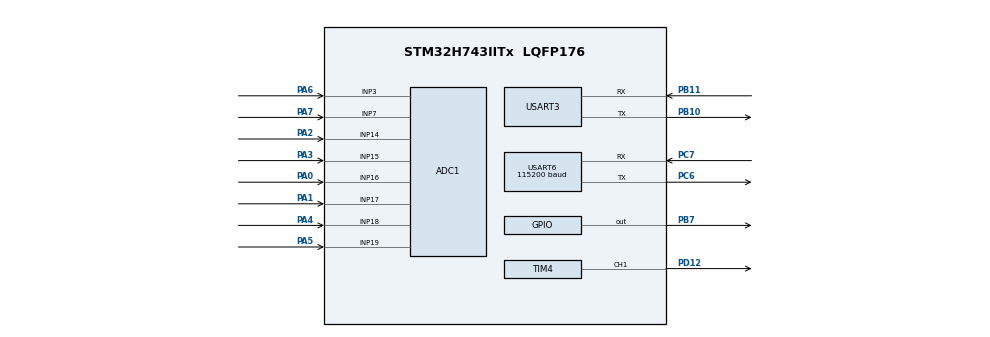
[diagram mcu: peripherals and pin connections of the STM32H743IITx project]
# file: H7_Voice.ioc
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ADC1.Channel-0\#ChannelRegularConversion=ADC_CHANNEL_16
ADC1.Channel-1\#ChannelRegularConversion=ADC_CHANNEL_17
ADC1.Channel-2\#ChannelRegularConversion=ADC_CHANNEL_14
ADC1.Channel-3\#ChannelRegularConversion=ADC_CHANNEL_15
ADC1.Channel-4\#ChannelRegularConversion=ADC_CHANNEL_18
ADC1.Channel-5\#ChannelRegularConversion=ADC_CHANNEL_19
ADC1.Channel-6\#ChannelRegularConversion=ADC_CHANNEL_3
ADC1.Channel-7\#ChannelRegularConversion=ADC_CHANNEL_7
ADC1.ContinuousConvMode=ENABLE
ADC1.ConversionDataManagement=ADC_CONVERSIONDATA_DMA_CIRCULAR
ADC1.NbrOfConversion=8
ADC1.NbrOfConversionFlag=1
ADC1.OffsetNumber-0\#ChannelRegularConversion=ADC_OFFSET_NONE
ADC1.OffsetNumber-1\#ChannelRegularConversion=ADC_OFFSET_NONE
ADC1.OffsetNumber-2\#ChannelRegularConversion=ADC_OFFSET_NONE
ADC1.OffsetNumber-3\#ChannelRegularConversion=ADC_OFFSET_NONE
ADC1.OffsetNumber-4\#ChannelRegularConversion=ADC_OFFSET_NONE
ADC1.OffsetNumber-5\#ChannelRegularConversion=ADC_OFFSET_NONE
ADC1.OffsetNumber-6\#ChannelRegularConversion=ADC_OFFSET_NONE
ADC1.OffsetNumber-7\#ChannelRegularConversion=ADC_OFFSET_NONE
ADC1.OffsetSignedSaturation-0\#ChannelRegularConversion=DISABLE
ADC1.OffsetSignedSaturation-1\#ChannelRegularConversion=DISABLE
ADC1.OffsetSignedSaturation-2\#ChannelRegularConversion=DISABLE
ADC1.OffsetSignedSaturation-3\#ChannelRegularConversion=DISABLE
ADC1.OffsetSignedSaturation-4\#ChannelRegularConversion=DISABLE
ADC1.OffsetSignedSaturation-5\#ChannelRegularConversion=DISABLE
ADC1.OffsetSignedSaturation-6\#ChannelRegularConversion=DISABLE
ADC1.OffsetSignedSaturation-7\#ChannelRegularConversion=DISABLE
ADC1.Rank-0\#ChannelRegularConversion=1
ADC1.Rank-1\#ChannelRegularConversion=2
ADC1.Rank-2\#ChannelRegularConversion=3
ADC1.Rank-3\#ChannelRegularConversion=4
ADC1.Rank-4\#ChannelRegularConversion=5
ADC1.Rank-5\#ChannelRegularConversion=6
ADC1.Rank-6\#ChannelRegularConversion=7
ADC1.Rank-7\#ChannelRegularConversion=8
ADC1.SamplingTime-0\#ChannelRegularConversion=ADC_SAMPLETIME_2CYCLES_5
ADC1.SamplingTime-1\#ChannelRegularConversion=ADC_SAMPLETIME_2CYCLES_5
ADC1.SamplingTime-2\#ChannelRegularConversion=ADC_SAMPLETIME_2CYCLES_5
ADC1.SamplingTime-3\#ChannelRegularConversion=ADC_SAMPLETIME_2CYCLES_5
ADC1.SamplingTime-4\#ChannelRegularConversion=ADC_SAMPLETIME_2CYCLES_5
ADC1.SamplingTime-5\#ChannelRegularConversion=ADC_SAMPLETIME_2CYCLES_5
ADC1.SamplingTime-6\#ChannelRegularConversion=ADC_SAMPLETIME_2CYCLES_5
ADC1.SamplingTime-7\#ChannelRegularConversion=ADC_SAMPLETIME_2CYCLES_5
ADC1.master=1
Dma.ADC1.0.Direction=DMA_PERIPH_TO_MEMORY
Dma.ADC1.0.EventEnable=DISABLE
Dma.ADC1.0.FIFOMode=DMA_FIFOMODE_DISABLE
Dma.ADC1.0.Instance=DMA1_Stream0
Dma.ADC1.0.MemDataAlignment=DMA_MDATAALIGN_HALFWORD
Dma.ADC1.0.MemInc=DMA_MINC_ENABLE
Dma.ADC1.0.Mode=DMA_CIRCULAR
Dma.ADC1.0.PeriphDataAlignment=DMA_PDATAALIGN_HALFWORD
Dma.ADC1.0.PeriphInc=DMA_PINC_DISABLE
Dma.ADC1.0.Polarity=HAL_DMAMUX_REQ_GEN_RISING
Dma.ADC1.0.Priority=DMA_PRIORITY_LOW
Dma.ADC1.0.RequestNumber=1
Dma.ADC1.0.SignalID=NONE
Dma.ADC1.0.SyncEnable=DISABLE
Dma.ADC1.0.SyncPolarity=HAL_DMAMUX_SYNC_NO_EVENT
Dma.ADC1.0.SyncRequestNumber=1
Dma.ADC1.0.SyncSignalID=NONE
Dma.Request0=ADC1
Mcu.Family=STM32H7
Mcu.Name=STM32H743IITx
Mcu.Package=LQFP176
NVIC.PriorityGroup=NVIC_PRIORITYGROUP_4
NVIC.TIM3_IRQn=true\:5\:0\:true\:false\:true\:true\:true\:true
NVIC.USART6_IRQn=true\:4\:0\:true\:false\:true\:true\:true\:true
PA0.Mode=IN16-Single-Ended
PA0.Signal=ADC1_INP16
PA1.Mode=IN17-Single-Ended
PA1.Signal=ADC1_INP17
PA2.Signal=ADCx_INP14
PA3.Signal=ADCx_INP15
PA4.Signal=ADCx_INP18
PA5.Signal=ADCx_INP19
PA6.Signal=ADCx_INP3
PA7.Signal=ADCx_INP7
PB10.Mode=Asynchronous
PB10.Signal=USART3_TX
PB11.Mode=Asynchronous
PB11.Signal=USART3_RX
PB7.Signal=GPIO_Output
PC6.Mode=Asynchronous
PC6.Signal=USART6_TX
PC7.Mode=Asynchronous
PC7.Signal=USART6_RX
PD12.Signal=S_TIM4_CH1
PH0-OSC_IN\ (PH0).Mode=HSE-External-Oscillator
PH0-OSC_IN\ (PH0).Signal=RCC_OSC_IN
PH1-OSC_OUT\ (PH1).Mode=HSE-External-Oscillator
PH1-OSC_OUT\ (PH1).Signal=RCC_OSC_OUT
ProjectManager.HeapSize=0x200
ProjectManager.StackSize=0x400
ProjectManager.TargetToolchain=STM32CubeIDE
RCC.ADCFreq_Value=75000000
RCC.APB1Freq_Value=120000000
RCC.APB2Freq_Value=120000000
RCC.APB3Freq_Value=120000000
RCC.APB4Freq_Value=120000000
RCC.CortexFreq_Value=480000000
RCC.D1PPRE=RCC_APB3_DIV2
RCC.D2PPRE1=RCC_APB1_DIV2
RCC.D2PPRE2=RCC_APB2_DIV2
RCC.D3PPRE=RCC_APB4_DIV2
RCC.DIVM1=5
RCC.DIVM2=2
RCC.DIVN1=192
RCC.DIVN2=12
RCC.HCLKFreq_Value=240000000
RCC.HPRE=RCC_HCLK_DIV2
RCC.PLLSourceVirtual=RCC_PLLSOURCE_HSE
RCC.SYSCLKFreq_VALUE=480000000
RCC.SYSCLKSource=RCC_SYSCLKSOURCE_PLLCLK
RCC.USBFreq_Value=480000000
SH.ADCx_INP14.0=ADC1_INP14,IN14-Single-Ended
SH.ADCx_INP15.0=ADC1_INP15,IN15-Single-Ended
SH.ADCx_INP18.0=ADC1_INP18,IN18-Single-Ended
SH.ADCx_INP19.0=ADC1_INP19,IN19-Single-Ended
SH.ADCx_INP3.0=ADC1_INP3,IN3-Single-Ended
SH.ADCx_INP7.0=ADC1_INP7,IN7-Single-Ended
SH.S_TIM4_CH1.0=TIM4_CH1,PWM Generation1 CH1
TIM2.Prescaler=239
TIM3.Period=149
TIM3.Prescaler=49
TIM4.Channel-PWM\ Generation1\ CH1=TIM_CHANNEL_1
TIM4.Period=5000-1
TIM4.Prescaler=240-1
TIM4.Pulse-PWM\ Generation1\ CH1=2500-1
USART3.VirtualMode-Asynchronous=VM_ASYNC
USART6.BaudRate=115200
USART6.VirtualMode-Asynchronous=VM_ASYNC
VP_TIM2_VS_ClockSourceINT.Mode=Internal
VP_TIM3_VS_ClockSourceINT.Mode=Internal
VP_TIM4_VS_ClockSourceINT.Mode=Internal
board=custom

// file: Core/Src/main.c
/* USER CODE BEGIN Header */
/**
  ******************************************************************************
  * @file           : main.c
  * @brief          : Main program body
  ******************************************************************************
  * @attention
  *
  * Copyright (c) 2022 STMicroelectronics.
  * All rights reserved.
  *
  * This software is licensed under terms that can be found in the LICENSE file
  * in the root directory of this software component.
  * If no LICENSE file comes with this software, it is provided AS-IS.
  *
  ******************************************************************************
  */
/* USER CODE END Header */
#include "main.h"
#include "adc.h"
#include "dma.h"
#include "tim.h"
#include "usart.h"
#include "gpio.h"

/* USER CODE BEGIN Includes */
#include "workman.h"
/* USER CODE END Includes */

/* USER CODE BEGIN PD */
#define RED_Pin GPIO_PIN_7
#define RED_GPIO_Port GPIOB
/* USER CODE END PD */

/* USER CODE BEGIN PV */
float adjust=0;
/* USER CODE END PV */

void SystemClock_Config(void);

int main(void)
{

  /* MCU Configuration--------------------------------------------------------*/

  /* Reset of all peripherals, Initializes the Flash interface and the Systick. */
  HAL_Init();

  /* Configure the system clock */
  SystemClock_Config();

  /* Initialize all configured peripherals */
  MX_DMA_Init();
  MX_GPIO_Init();
  MX_ADC1_Init();
  MX_TIM2_Init();
  MX_TIM3_Init();
  MX_TIM4_Init();
  MX_USART6_UART_Init();

  MX_USART3_UART_Init();
  /* USER CODE BEGIN 2 */
  init_start();
  /* USER CODE END 2 */

  /* Infinite loop */
  while (1)
  {

    /* USER CODE BEGIN 3 */
	  while_do();

  }
  /* USER CODE END 3 */
}

void SystemClock_Config(void)
{
  RCC_OscInitTypeDef RCC_OscInitStruct = {0};
  RCC_ClkInitTypeDef RCC_ClkInitStruct = {0};

  /** Supply configuration update enable
  */
  HAL_PWREx_ConfigSupply(PWR_LDO_SUPPLY);

  /** Configure the main internal regulator output voltage
  */
  __HAL_PWR_VOLTAGESCALING_CONFIG(PWR_REGULATOR_VOLTAGE_SCALE1);

  while(!__HAL_PWR_GET_FLAG(PWR_FLAG_VOSRDY)) {}

  __HAL_RCC_SYSCFG_CLK_ENABLE();
  __HAL_PWR_VOLTAGESCALING_CONFIG(PWR_REGULATOR_VOLTAGE_SCALE0);

  while(!__HAL_PWR_GET_FLAG(PWR_FLAG_VOSRDY)) {}

  /** Macro to configure the PLL clock source
  */
  __HAL_RCC_PLL_PLLSOURCE_CONFIG(RCC_PLLSOURCE_HSE);

  /** Initializes the RCC Oscillators according to the specified parameters
  * in the RCC_OscInitTypeDef structure.
  */
  RCC_OscInitStruct.OscillatorType = RCC_OSCILLATORTYPE_HSE;
  RCC_OscInitStruct.HSEState = RCC_HSE_ON;
  RCC_OscInitStruct.PLL.PLLState = RCC_PLL_ON;
  RCC_OscInitStruct.PLL.PLLSource = RCC_PLLSOURCE_HSE;
  RCC_OscInitStruct.PLL.PLLM = 5;
  RCC_OscInitStruct.PLL.PLLN = 192;
  RCC_OscInitStruct.PLL.PLLP = 2;
  RCC_OscInitStruct.PLL.PLLQ = 2;
  RCC_OscInitStruct.PLL.PLLR = 2;
  RCC_OscInitStruct.PLL.PLLRGE = RCC_PLL1VCIRANGE_2;
  RCC_OscInitStruct.PLL.PLLVCOSEL = RCC_PLL1VCOWIDE;
  RCC_OscInitStruct.PLL.PLLFRACN = 0;
  if (HAL_RCC_OscConfig(&RCC_OscInitStruct) != HAL_OK)
  {
    Error_Handler();
  }

  /** Initializes the CPU, AHB and APB buses clocks
  */
  RCC_ClkInitStruct.ClockType = RCC_CLOCKTYPE_HCLK|RCC_CLOCKTYPE_SYSCLK
                              |RCC_CLOCKTYPE_PCLK1|RCC_CLOCKTYPE_PCLK2
                              |RCC_CLOCKTYPE_D3PCLK1|RCC_CLOCKTYPE_D1PCLK1;
  RCC_ClkInitStruct.SYSCLKSource = RCC_SYSCLKSOURCE_PLLCLK;
  RCC_ClkInitStruct.SYSCLKDivider = RCC_SYSCLK_DIV1;
  RCC_ClkInitStruct.AHBCLKDivider = RCC_HCLK_DIV2;
  RCC_ClkInitStruct.APB3CLKDivider = RCC_APB3_DIV2;
  RCC_ClkInitStruct.APB1CLKDivider = RCC_APB1_DIV2;
  RCC_ClkInitStruct.APB2CLKDivider = RCC_APB2_DIV2;
  RCC_ClkInitStruct.APB4CLKDivider = RCC_APB4_DIV2;

  if (HAL_RCC_ClockConfig(&RCC_ClkInitStruct, FLASH_LATENCY_4) != HAL_OK)
  {
    Error_Handler();
  }
}

void Error_Handler(void)
{
  __disable_irq();
  while (1)
  {
  }
}
